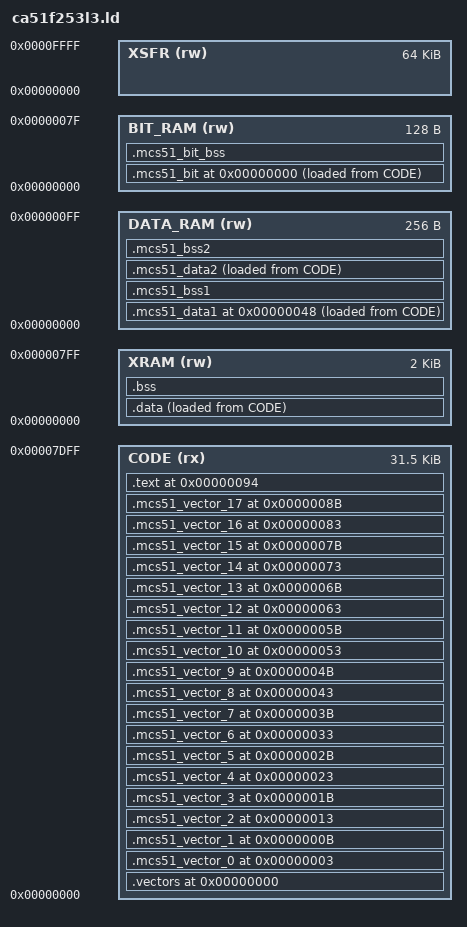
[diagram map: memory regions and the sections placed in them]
/* CA51F253L3 linker profile for the mcs51-llvm (clang/lld) toolchain.
 * Memory map matches the SDCC build: --code-size FLASH_CODE_SIZE (data flash
 * starts at 0x7E00), --xram-size 2048, classic 256-byte internal RAM.
 * CODE and XDATA are independent 8051 address buses, so their VMAs overlap.
 * SFR/XSFR absolute symbols are supplied by a second -T script generated by
 * tools/gen_clang_sfr.py. */
ENTRY(reset)

MEMORY
{
  CODE      (rx) : ORIGIN = 0x0000, LENGTH = 0x7E00
  XRAM      (rw) : ORIGIN = 0x0000, LENGTH = 0x0800
  DATA_RAM  (rw) : ORIGIN = 0x0000, LENGTH = 0x0100
  BIT_RAM   (rw) : ORIGIN = 0x0000, LENGTH = 0x0080
  /* XDATA-mapped registers (ca51f2xsfr.h): only used by the generated      */
  /* empty NOLOAD sections in sfr_symbols.ld, so lld's space check sees    */
  /* the MOVX targets as XDATA. Nothing is emitted into the flash image.    */
  XSFR      (rw) : ORIGIN = 0x0000, LENGTH = 0x10000
}

/* DATA/IDATA globals would occupy 0x48..0x7F (0x30..0x47 hold the backend's
 * imaginary registers, the upper half of internal RAM is the hardware
 * stack). This project has no global DATA/IDATA objects - the sections below
 * stay empty and the ASSERTs at the bottom fail loudly if that changes. */
__ca51f2_static_data_start = 0x48;
__ca51f2_static_data_end = 0x80;

SECTIONS
{
  .vectors 0x0000 : { KEEP(*(.vectors)) } > CODE

  .mcs51_vector_0 0x0003 : { KEEP(*(.mcs51.vector.0)) } > CODE
  .mcs51_vector_1 0x000b : { KEEP(*(.mcs51.vector.1)) } > CODE
  .mcs51_vector_2 0x0013 : { KEEP(*(.mcs51.vector.2)) } > CODE
  .mcs51_vector_3 0x001b : { KEEP(*(.mcs51.vector.3)) } > CODE
  .mcs51_vector_4 0x0023 : { KEEP(*(.mcs51.vector.4)) } > CODE
  .mcs51_vector_5 0x002b : { KEEP(*(.mcs51.vector.5)) } > CODE
  .mcs51_vector_6 0x0033 : { KEEP(*(.mcs51.vector.6)) } > CODE
  .mcs51_vector_7 0x003b : { KEEP(*(.mcs51.vector.7)) } > CODE
  .mcs51_vector_8 0x0043 : { KEEP(*(.mcs51.vector.8)) } > CODE
  .mcs51_vector_9 0x004b : { KEEP(*(.mcs51.vector.9)) } > CODE
  .mcs51_vector_10 0x0053 : { KEEP(*(.mcs51.vector.10)) } > CODE
  .mcs51_vector_11 0x005b : { KEEP(*(.mcs51.vector.11)) } > CODE
  .mcs51_vector_12 0x0063 : { KEEP(*(.mcs51.vector.12)) } > CODE
  .mcs51_vector_13 0x006b : { KEEP(*(.mcs51.vector.13)) } > CODE
  .mcs51_vector_14 0x0073 : { KEEP(*(.mcs51.vector.14)) } > CODE
  .mcs51_vector_15 0x007b : { KEEP(*(.mcs51.vector.15)) } > CODE
  .mcs51_vector_16 0x0083 : { KEEP(*(.mcs51.vector.16)) } > CODE
  .mcs51_vector_17 0x008b : { KEEP(*(.mcs51.vector.17)) } > CODE

  /* Vector slots occupy 0x0003..0x008d; code starts right after. */
  .text 0x0094 :
  {
    *(.mcs51.common .mcs51.common.*)
    *(.text .text.*)
    *(.rodata .rodata.*)
    *(.mcs51.code.rodata .mcs51.code.rodata.*)
  } > CODE

  /* Initialized XDATA globals. Their flash load image is NOT copied by the
   * startup: this project's main() begins with xdata_clear() which owns the
   * whole XRAM initial state (the SDCC build never copied it either - XISEG
   * initialisers are disabled). The section is kept so that LLD accepts the
   * initialized-XDATA sections and so the load image stays inspectable. */
  .data :
  {
    __mcs51_data_start = .;
    *(.data .data.*)
    *(.mcs51.xdata.init .mcs51.xdata.init.*)
    __mcs51_data_end = .;
  } > XRAM AT> CODE
  __mcs51_data_load = LOADADDR(.data);
  .bss (NOLOAD) :
  {
    *(.bss .bss.*)
    *(.mcs51.xdata.bss .mcs51.xdata.bss.*)
    *(COMMON)
  } > XRAM

  /* DATA/IDATA address spaces (unused; kept for a clear error if a global
   * object ever appears). */
  .mcs51_data1 __ca51f2_static_data_start :
  {
    __mcs51_data1_start = .;
    *(.mcs51.data1)
    __mcs51_data1_end = .;
  } > DATA_RAM AT> CODE
  __mcs51_data1_load = LOADADDR(.mcs51_data1);
  .mcs51_bss1 (NOLOAD) :
  {
    *(.mcs51.data1.bss)
    __mcs51_data1_bss_end = .;
  } > DATA_RAM

  .mcs51_data2 :
  {
    __mcs51_data2_start = .;
    *(.mcs51.data2)
    __mcs51_data2_end = .;
  } > DATA_RAM AT> CODE
  __mcs51_data2_load = LOADADDR(.mcs51_data2);
  .mcs51_bss2 (NOLOAD) :
  {
    *(.mcs51.data2.bss)
    __mcs51_data2_bss_end = .;
  } > DATA_RAM

  /* Bit-address-space globals: bit addresses 0..127 backed by internal RAM
   * bytes 0x20..0x2F (cleared by the startup IRAM pass). Initialized bit
   * globals would be merged from CODE; this project uses none. */
  .mcs51_bit 0 :
  {
    __mcs51_bit_start = .;
    *(.mcs51.bit)
    __mcs51_bit_end = .;
  } > BIT_RAM AT> CODE
  __mcs51_bit_load = LOADADDR(.mcs51_bit);
  .mcs51_bit_bss (NOLOAD) :
  {
    *(.mcs51.bit.bss)
    __mcs51_bit_bss_end = .;
  } > BIT_RAM

  /* SFR/SBIT absolute symbols and the XSFR register sections (generated). */
  INCLUDE build/gen/sfr_symbols.ld
}

ASSERT(ADDR(.text) + SIZEOF(.text) <= 0x7E00,
       "CA51F253L3 code exceeds the flash code area")
ASSERT(ADDR(.bss) + SIZEOF(.bss) <= 0x0800,
       "CA51F253L3 XDATA globals exceed 2048 bytes")
ASSERT(SIZEOF(.mcs51_data1) == 0 && SIZEOF(.mcs51_bss1) == 0,
       "CA51F253L3 has no startup support for global DATA objects")
ASSERT(SIZEOF(.mcs51_data2) == 0 && SIZEOF(.mcs51_bss2) == 0,
       "CA51F253L3 has no startup support for global IDATA objects")
ASSERT(__mcs51_bit_bss_end <= LENGTH(BIT_RAM),
       "CA51F253L3 bit globals exceed the bit-addressable area")
ASSERT(SIZEOF(.mcs51_vector_0) <= 3,
       "CA51F253L3 interrupt vector 0 has multiple handlers")
ASSERT(SIZEOF(.mcs51_vector_1) <= 3,
       "CA51F253L3 interrupt vector 1 has multiple handlers")
ASSERT(SIZEOF(.mcs51_vector_2) <= 3,
       "CA51F253L3 interrupt vector 2 has multiple handlers")
ASSERT(SIZEOF(.mcs51_vector_3) <= 3,
       "CA51F253L3 interrupt vector 3 has multiple handlers")
ASSERT(SIZEOF(.mcs51_vector_4) <= 3,
       "CA51F253L3 interrupt vector 4 has multiple handlers")
ASSERT(SIZEOF(.mcs51_vector_5) <= 3,
       "CA51F253L3 interrupt vector 5 has multiple handlers")
ASSERT(SIZEOF(.mcs51_vector_6) <= 3,
       "CA51F253L3 interrupt vector 6 has multiple handlers")
ASSERT(SIZEOF(.mcs51_vector_7) <= 3,
       "CA51F253L3 interrupt vector 7 has multiple handlers")
